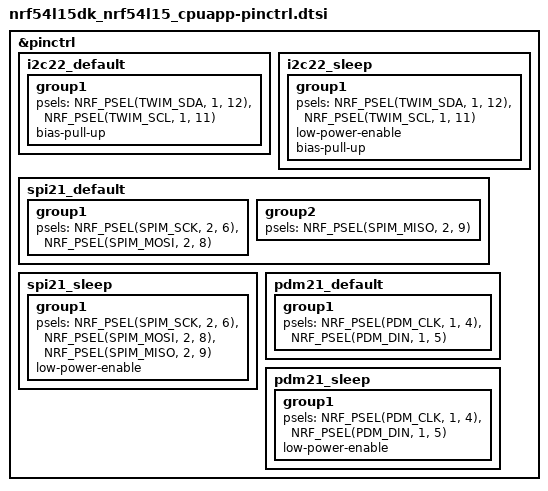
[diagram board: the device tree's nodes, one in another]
/*
 * Copyright (c) 2025 Sensry GmbH
 * SPDX-License-Identifier: Apache-2.0
 */

&pinctrl {
	i2c22_default: i2c22_default {
		group1 {
			psels = <NRF_PSEL(TWIM_SDA, 1, 12)>,
				<NRF_PSEL(TWIM_SCL, 1, 11)>;
			bias-pull-up;
		};
	};

	i2c22_sleep: i2c22_sleep {
		group1 {
			psels = <NRF_PSEL(TWIM_SDA, 1, 12)>,
				<NRF_PSEL(TWIM_SCL, 1, 11)>;
			low-power-enable;
			bias-pull-up;
		};
	};

	spi21_default: spi21_default {
		group1 {
			psels = <NRF_PSEL(SPIM_SCK, 2, 6)>,
				<NRF_PSEL(SPIM_MOSI, 2, 8)>;
		};

		group2 {
			psels = <NRF_PSEL(SPIM_MISO, 2, 9)>;
		};
	};

	spi21_sleep: spi21_sleep {
		group1 {
			psels = <NRF_PSEL(SPIM_SCK, 2, 6)>,
				<NRF_PSEL(SPIM_MOSI, 2, 8)>,
				<NRF_PSEL(SPIM_MISO, 2, 9)>;
			low-power-enable;
		};
	};

	pdm21_default: pdm21_default {
		group1 {
			psels = <NRF_PSEL(PDM_CLK, 1, 4)>,
				<NRF_PSEL(PDM_DIN, 1, 5)>;
		};
	};

	pdm21_sleep: pdm21_sleep {
		group1 {
			psels = <NRF_PSEL(PDM_CLK, 1, 4)>,
				<NRF_PSEL(PDM_DIN, 1, 5)>;
			low-power-enable;
		};
	};
};
